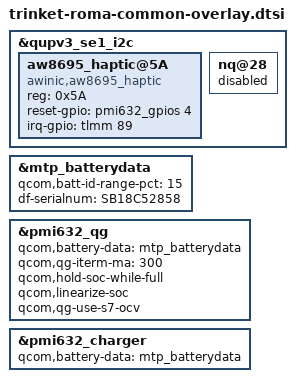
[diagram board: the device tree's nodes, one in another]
/* Copyright (c) 2018, The Linux Foundation. All rights reserved.
 *
 * This program is free software; you can redistribute it and/or modify
 * it under the terms of the GNU General Public License version 2 and
 * only version 2 as published by the Free Software Foundation.
 *
 * This program is distributed in the hope that it will be useful,
 * but WITHOUT ANY WARRANTY; without even the implied warranty of
 * MERCHANTABILITY or FITNESS FOR A PARTICULAR PURPOSE.  See the
 * GNU General Public License for more details.
 */

#include "trinket-moto-common-overlay.dtsi"
#include "roma-panel.dtsi"
#include "trinket-roma-fps-overlay.dtsi"
#include "trinket-roma-touch-overlay.dtsi"
#include "trinket-roma-audio-overlay.dtsi"

&qupv3_se1_i2c {
	status = "ok";
	aw8695_haptic@5A {
	    compatible = "awinic,aw8695_haptic";
	    reg = <0x5A>;
	    reset-gpio = <&pmi632_gpios 4 0>;
	    irq-gpio = <&tlmm 89 0>;
	    status = "okay";
	};

	nq@28 {
	    status = "disabled";
	};
};

&mtp_batterydata {
	qcom,batt-id-range-pct = <15>;
	df-serialnum = "SB18C52858";
	#include "qg-batterydata-kd40-scud-4000mah.dtsi"
};

&pmi632_qg {
	qcom,battery-data = <&mtp_batterydata>;
	qcom,qg-iterm-ma = <300>;
	qcom,hold-soc-while-full;
	qcom,linearize-soc;
	qcom,qg-use-s7-ocv;
};

&pmi632_charger {
	qcom,battery-data = <&mtp_batterydata>;
};
